# nrf54lm20a_enga_application register map
Vendor: Nordic Semiconductor; Series: nrf54l; File version: 1
CPU: CM33 r0p4, little endian, MPU, FPU, 3 interrupt priority bits, 270 interrupts, 4 SAU regions
Registers are 32-bit, read-write, reset 0x0 unless marked. A register's access mark holds for its fields unless they carry their own. Offsets are from the block's base; [hi:lo] are bit positions; lines under a group give offsets from that group; {n}, {i} and the like mark numbered series; 'fields as' and 'values as' point back to an identical list.

## GLOBAL_GPIOHSPADCTRL_S — GPIO high-speed pad control
Base 0x50050400
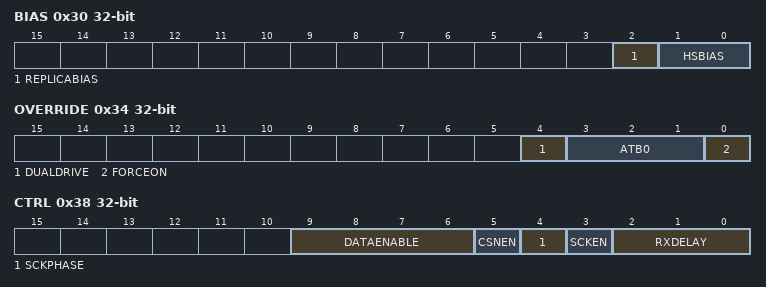
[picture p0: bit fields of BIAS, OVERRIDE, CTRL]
0x30 BIAS — Bias control
  [2] REPLICABIAS — Slew setting for replica clock (used by the VPR coprocessor for emulating a QSPI peripheral)
  [1:0] HSBIAS — Slew setting for high-speed pad (higher value is faster)
0x34 OVERRIDE — Override control
  [4] DUALDRIVE — Drive pad from both high-speed pad and regular pad (when highspeed is enabled)
  [3:1] ATB0 — ATB0 settings
    7=BiasTrim (Unspecified); 6=BiasSupply (Unspecified); 5=BiasPTAT (Unspecified)
  [0] FORCEON
0x38 CTRL — Input sampling and buffering control (used by the VPR coprocessor for emulating a QSPI peripheral)
  [9:6] DATAENABLE — Enable delayed sampling
    0=Disabled (Delayed sampling is disabled); 15=Enabled (Delayed sampling is enabled)
  [5] CSNEN — Enable CSN synchronization of sampling
    0=Enabled (Delay chain is reset on active edge of CSN); 1=Disabled (Delay chain is not reset on active edge of CSN)
  [4] SCKPHASE
    0=Inverted (Invert SCK phase); 1=Non-inverted SCK phase
  [3] SCKEN — Enable SCK
    0=Disabled (Delay chain is reset and delayed sampling is disabled); 1=Enabled (Delay chain and delayed sampling is active)
  [2:0] RXDELAY — Delay selection

## GLOBAL_GPIOINTERNALP2_NS — GPIO Internal 0
Base 0x40051E00
Same registers: GLOBAL_GPIOINTERNALP1_NS 0x400D9E00, GLOBAL_GPIOINTERNALP0_NS 0x4010BE00, GLOBAL_GPIOINTERNALP2_S 0x50051E00, GLOBAL_GPIOINTERNALP1_S 0x500D9E00, GLOBAL_GPIOINTERNALP0_S 0x5010BE00
0x40 LATCHCLRWAITCNT reset 0x2 — Select the number of wait cycles inserted on the bus when a LATCH register is cleared.
  [1:0] LATCHCLRWAITCNT
0x44 FORCELDETECTLOWCNT reset 0x8 — Select the number of cycles that LDETECT is forced low after clearing a LATCH register.
  [3:0] FORCELDETECTLOWCNT
0x48 RESET — Reset all GPIO registers.
  [0] RESET
    1=RESET (Trigger reset); 0=NA (No effect)
0x4C SENSECONFIGCHANGECNT reset 0x3 — Selects the number of cycles before the SENSE configuration takes effect when it is changed. Setting this register lower than the reset value can lead to unwanted LATCH set when SENSE and INPUT fields (PIN[n].CNF) are changed simultaneously.
  [2:0] SENSECONFIGCHANGECNT — Selects the number of cycles before the SENSE configuration takes effect when it is changed.
0x160 PCGC group — Unspecified
  {0x20+4j} PENALTY[{j}] (j=0..3) ro — Description collection: Penalty level for power/clock pair n
    [1:0] PENALTY — Penalty level
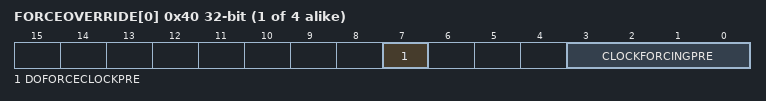
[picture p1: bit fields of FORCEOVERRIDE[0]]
  {0x40+4j} FORCEOVERRIDE[{j}] (j=0..3) ro — Description collection: Force override of power/clock pair n
    [7] DOFORCECLOCKPRE, [3:0] CLOCKFORCINGPRE

## GLOBAL_CTRLAP_NS — Control access port 0
Base 0x40052000; alternate view of GLOBAL_GPIOINTERNALP2_NS
Same registers: GLOBAL_CTRLAP_S 0x50052000 (alternate view of GLOBAL_GPIOINTERNALP2_S)
0x100 EVENTS_RXREADY — RXSTATUS is changed to DataPending.
  [0] EVENTS_RXREADY
    0=NotGenerated (Event not generated); 1=Generated (Event generated)
0x104 EVENTS_TXDONE — TXSTATUS is changed to NoDataPending.
  [0] EVENTS_TXDONE
    values as EVENTS_RXREADY.EVENTS_RXREADY
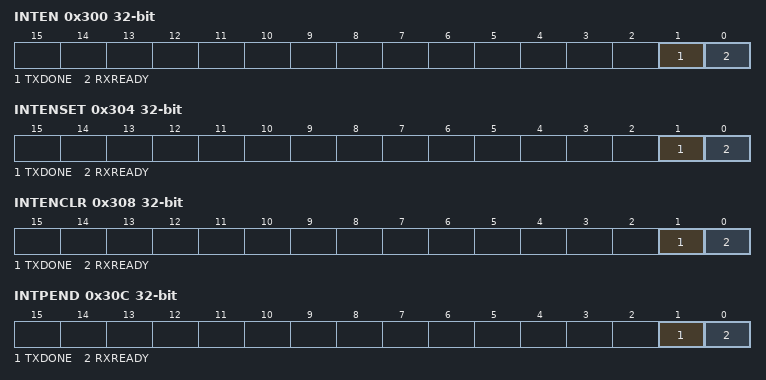
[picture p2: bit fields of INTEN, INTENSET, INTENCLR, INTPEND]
0x300 INTEN — Enable or disable interrupt
  [1] TXDONE — Enable or disable interrupt for event TXDONE
    0=Disabled; 1=Enabled
  [0] RXREADY — Enable or disable interrupt for event RXREADY
    0=Disabled; 1=Enabled
0x304 INTENSET — Enable interrupt
  [1] TXDONE — Write '1' to enable interrupt for event TXDONE
    on read: 0=Disabled (Read: Disabled); 1=Enabled (Read: Enabled) | on write: 1=Set (Enable)
  [0] RXREADY — Write '1' to enable interrupt for event RXREADY
    values as TXDONE
0x308 INTENCLR — Disable interrupt
  [1] TXDONE — Write '1' to disable interrupt for event TXDONE
    on read: 0=Disabled (Read: Disabled); 1=Enabled (Read: Enabled) | on write: 1=Clear (Disable)
  [0] RXREADY — Write '1' to disable interrupt for event RXREADY
    values as TXDONE
0x30C INTPEND ro — Pending interrupts
  [1] TXDONE — Read pending status of interrupt for event TXDONE
    on read: 0=NotPending (Read: Not pending); 1=Pending (Read: Pending)
  [0] RXREADY — Read pending status of interrupt for event RXREADY
    values as TXDONE
0x400 MAILBOX group — Unspecified
  0x00 RXDATA ro — Data sent from the debugger to the CPU.
    [31:0] RXDATA — Data received from debugger.
  0x04 RXSTATUS ro — Status to indicate if data sent from the debugger to the CPU has been read.
    [0] RXSTATUS — Status of data in register RXDATA.
      0=NoDataPending (No data is pending in register RXDATA.); 1=DataPending (Data is pending in register RXDATA.)
  0x80 TXDATA — Data sent from the CPU to the debugger.
    [31:0] TXDATA — Data sent to debugger.
  0x84 TXSTATUS ro — Status to indicate if data sent from the CPU to the debugger has been read.
    [0] TXSTATUS — Status of data in register TXDATA.
      0=NoDataPending (No data is pending in register TXDATA.); 1=DataPending (Data is pending in register TXDATA.)
0x500 ERASEPROTECT group — Unspecified
  0x00 LOCK rw-once — This register locks the ERASEPROTECT.DISABLE register from being written until next reset.
    [0] LOCK — Lock ERASEPROTECT.DISABLE register from being written until next reset.
      0=Unlocked (Register ERASEPROTECT.DISABLE is writeable.); 1=Locked (Register ERASEPROTECT.DISABLE is read-only.)
  0x04 DISABLE write-once — This register disables the ERASEPROTECT register and performs an ERASEALL operation.
    [31:0] KEY — The ERASEALL sequence is initiated if the value of the KEY fields are non-zero and the KEY fields match on both the CPU and debugger sides.
0x520 RESET wo — System reset request.
  [2:0] RESET — Reset request
    0=No reset is generated; 1=SoftReset (Perform a device soft reset); 2=HardReset (Perform a device hard reset); 4=PinReset (Perform a device pin reset)
0x600 INFO group — Unspecified
  0x00 PARTNO write-once — Part number of the device.
    [31:0] PARTNO — Part number.
  0x04 HWREVISION write-once — Hardware Revision of the device.
    [31:0] ID — Part Variant.
